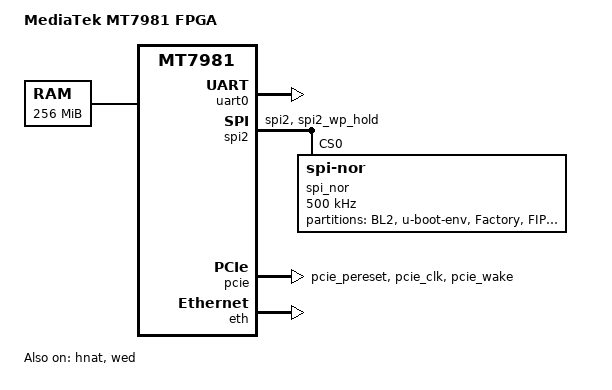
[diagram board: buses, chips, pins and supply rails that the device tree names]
/dts-v1/;
#include "mt7981-fpga.dtsi"
/ {
	model = "MediaTek MT7981 FPGA";
	compatible = "mediatek,mt7981-fpga-nor";
	chosen {
		bootargs = "console=ttyS0,115200n1 loglevel=8  \
				earlycon=uart8250,mmio32,0x11002000";
	};

	memory {
		// fpga ddr2: 128MB*2
		reg = <0 0x40000000 0 0x10000000>;
	};

        wsys_adie: wsys_adie@0 {
		// fpga cases need to manual change adie_id / sku_type for dvt only
                compatible = "mediatek,rebb-mt7981-adie";
                adie_id = <7976>;
                sku_type = <3000>;
        };
};

&uart0 {
	status = "okay";
};

&spi1 {
	pinctrl-names = "default";
	/* pin shared with snfi */
	pinctrl-0 = <&spic_pins>;
	status = "disabled";
};

&spi2 {
	pinctrl-names = "default";
	pinctrl-0 = <&spi2_flash_pins>;
	status = "okay";
	spi_nor@0 {
		#address-cells = <1>;
		#size-cells = <1>;
		compatible = "jedec,spi-nor";
		reg = <0>;
		spi-max-frequency = <500000>;

		partition@00000 {
			label = "BL2";
			reg = <0x00000 0x0040000>;
		};
		partition@40000 {
			label = "u-boot-env";
			reg = <0x40000 0x0010000>;
		};
		factory: partition@50000 {
			label = "Factory";
			reg = <0x50000 0x00B0000>;
		};
		partition@100000 {
			label = "FIP";
			reg = <0x100000 0x0080000>;
		};
		partition@180000 {
			label = "firmware";
			reg = <0x180000 0xE00000>;
		};
	};
};

&pcie {
	pinctrl-names = "default";
	pinctrl-0 = <&pcie_pins>;
	status = "okay";
};

&pio {
	pcie_pins: pcie-pins {
		mux {
			function = "pcie";
			groups = "pcie_pereset", "pcie_clk", "pcie_wake";
		};
	};

	spic_pins: spi1-pins {
		mux {
			function = "spi";
			groups = "spi1_1";
		};
	};

	spi2_flash_pins: spi2-pins {
		mux {
			function = "spi";
			groups = "spi2", "spi2_wp_hold";
		};
	};
};

&watchdog {
	status = "disabled";
};

&eth {
        status = "okay";

        gmac0: mac@0 {
                compatible = "mediatek,eth-mac";
                reg = <0>;
                phy-mode = "rgmii";

                fixed-link {
                        speed = <100>;
                        full-duplex;
                        pause;
                };
        }; 
	gmac1: mac@1 {
                compatible = "mediatek,eth-mac";
                reg = <1>;
                phy-mode = "rgmii";

                fixed-link {
                        speed = <100>;
                        full-duplex;
                        pause;
                };
        };

        mdio: mdio-bus {
                #address-cells = <1>;
                #size-cells = <0>;
        };

}; 

&hnat {
	mtketh-wan = "eth1";
	mtketh-lan = "eth0";
	mtketh-max-gmac = <2>;
	status = "okay";
};

&wed {
	dy_txbm_enable = "true";
	dy_txbm_budge = <8>;
	txbm_init_sz = <10>;
	status = "okay";
};

